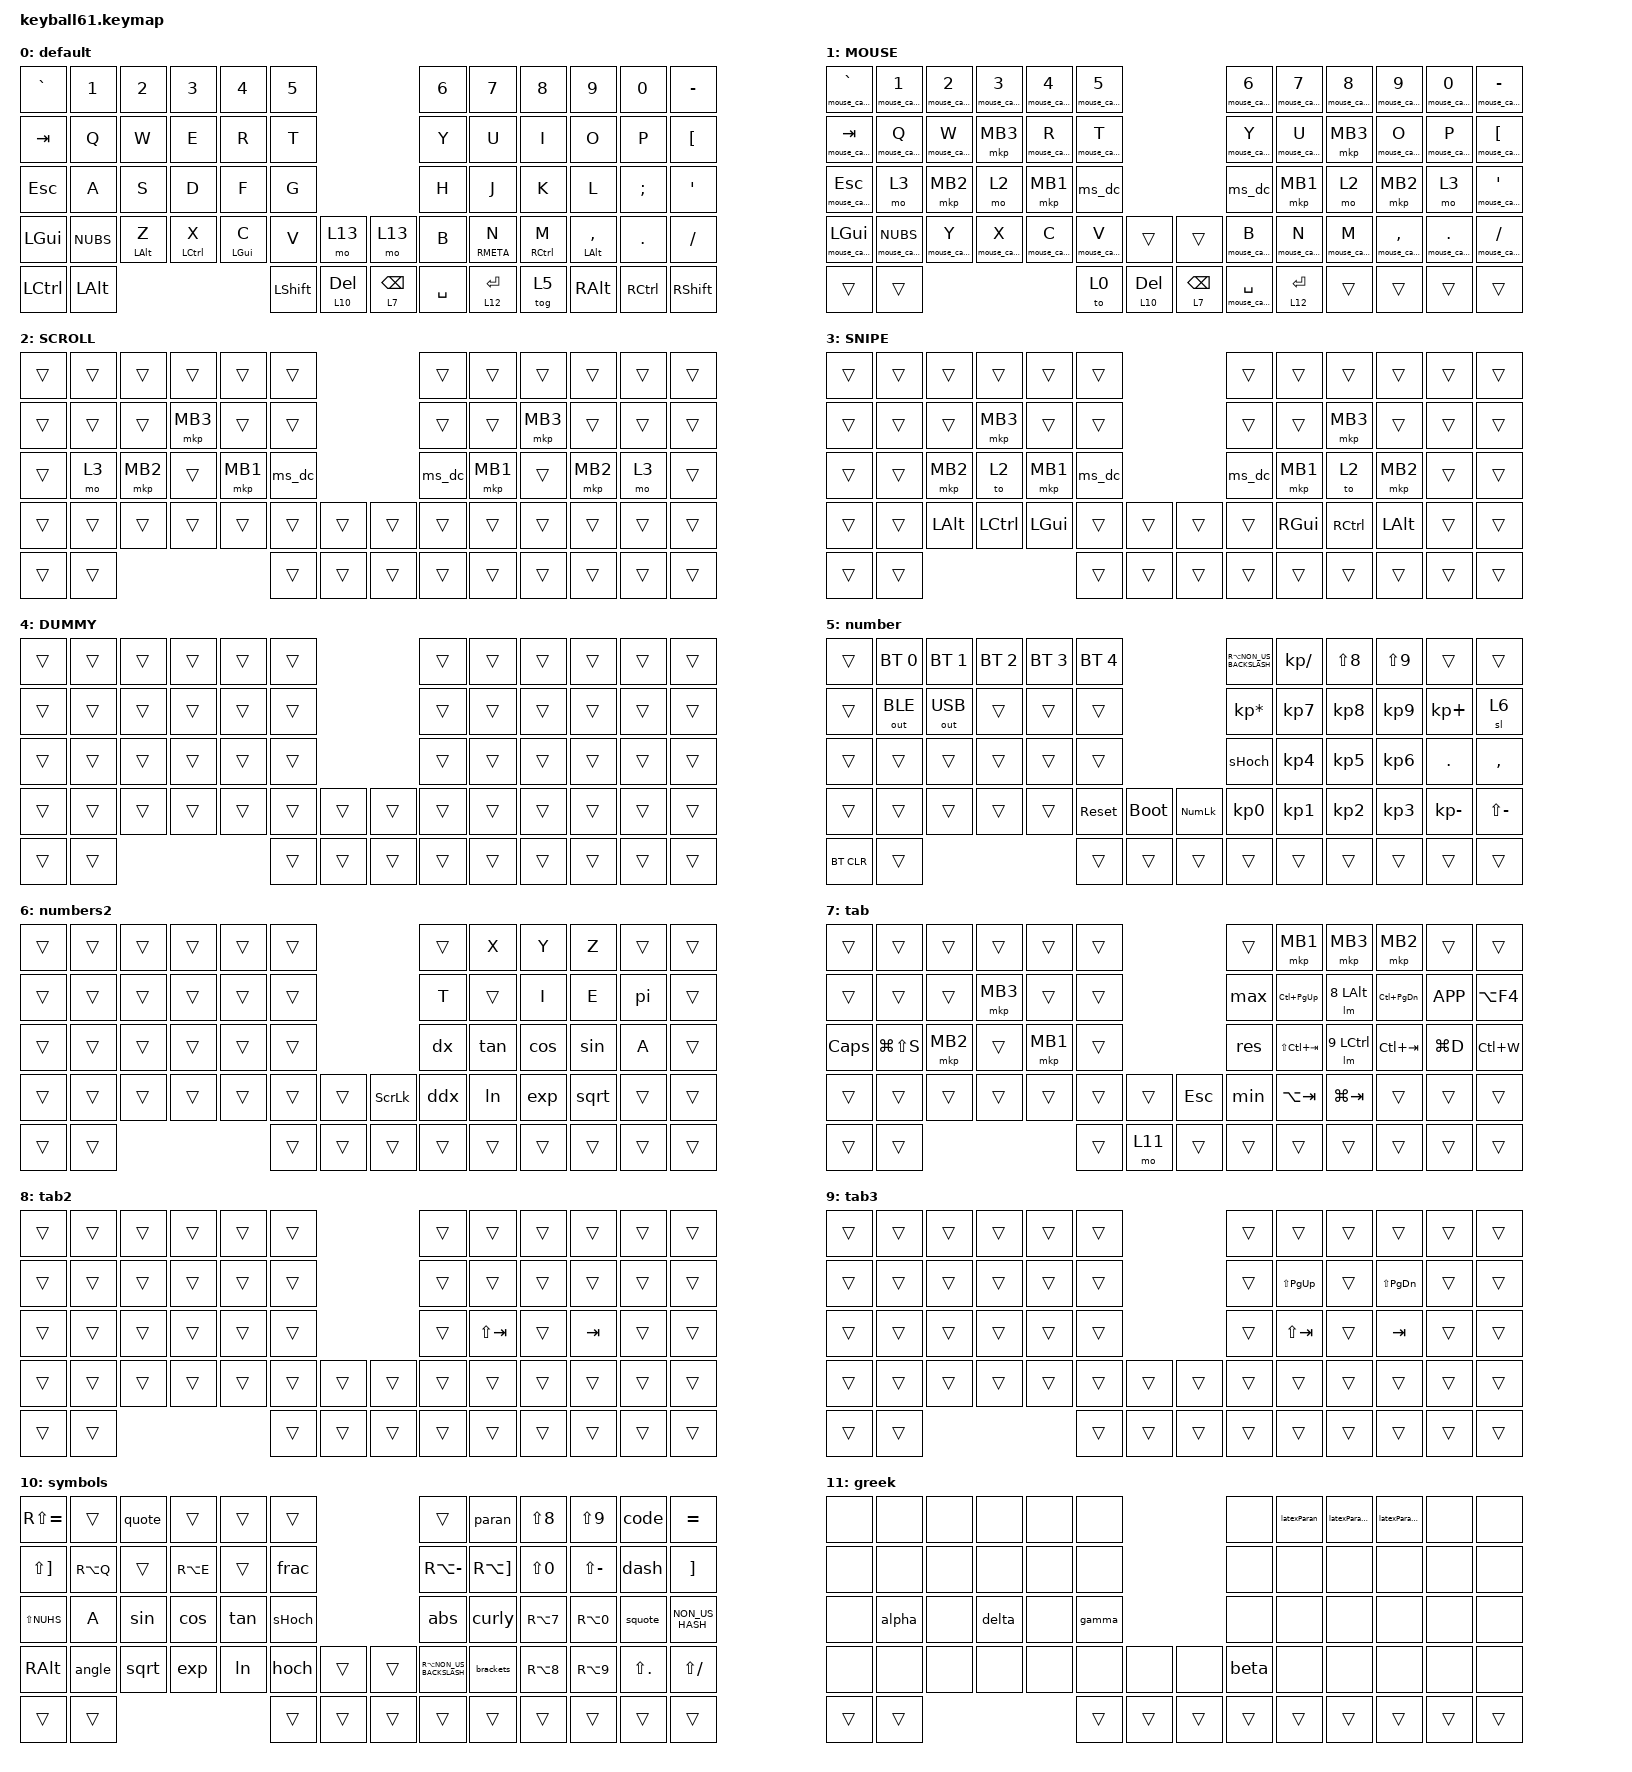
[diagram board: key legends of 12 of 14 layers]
#define DEFAULT 0
#define SYM     1
#define FUN     2
#define MOUSE   3
#define SCROLL  4
#define SNIPE   5

#include <behaviors/mouse_keys.dtsi>
#include <dt-bindings/zmk/mouse.h>
#include <behaviors.dtsi>
#include <dt-bindings/zmk/bt.h>
#include <dt-bindings/zmk/keys.h>
#include <dt-bindings/zmk/outputs.h>
#include <dt-bindings/zmk/pointing.h>

&lt {
    tapping-term-ms = <240>;
    flavor = "balanced";
    quick-tap-ms = <150>;
};

&mt {
    tapping-term-ms = <200>;
    flavor = "tap-preferred";
    quick-tap-ms = <150>;
};

/ {
    macros {
        lm: lm {
            compatible = "zmk,behavior-macro-two-param";
            #binding-cells = <2>;
            bindings =
                <&macro_param_1to1>,
                <&macro_press>,
                <&mo MACRO_PLACEHOLDER &macro_param_2to1>,
                <&macro_press>,
                <&kp MACRO_PLACEHOLDER>,
                <&macro_pause_for_release>,
                <&macro_param_2to1>,
                <&macro_release>,
                <&kp MACRO_PLACEHOLDER &macro_param_1to1>,
                <&macro_release>,
                <&mo MACRO_PLACEHOLDER>;

            label = "LM";
        };

        curly: curly {
            compatible = "zmk,behavior-macro";
            #binding-cells = <0>;
            bindings = <&kp RA(N7) &kp RA(N0) &kp LEFT>;
            label = "CURLY";
        };

        paran: paran {
            compatible = "zmk,behavior-macro";
            #binding-cells = <0>;
            bindings = <&kp LS(N8) &kp LS(N9) &kp LEFT>;
            label = "PARAN";
        };

        angle: angle {
            compatible = "zmk,behavior-macro";
            #binding-cells = <0>;
            bindings = <&kp NON_US_BACKSLASH &kp LS(NON_US_BACKSLASH) &kp LEFT>;
            label = "angle";
        };

        brackets: brackets {
            compatible = "zmk,behavior-macro";
            #binding-cells = <0>;
            bindings = <&kp RA(N8) &kp RA(N9) &kp LEFT>;
            label = "BRACKETS";
        };

        abs: abs {
            compatible = "zmk,behavior-macro";
            #binding-cells = <0>;
            bindings = <&kp RA(NON_US_BACKSLASH) &kp RA(NON_US_BACKSLASH) &kp LEFT>;
            label = "ABS";
        };

        code: code {
            compatible = "zmk,behavior-macro";
            #binding-cells = <0>;
            bindings = <&kp LS(EQUAL) &kp LS(EQUAL) &kp LS(EQUAL) &kp SPACE &kp ENTER>;
            label = "CODE";
        };

        quote: quote {
            compatible = "zmk,behavior-macro";
            #binding-cells = <0>;
            bindings = <&kp LS(N2) &kp LS(N2) &kp LEFT>;
            label = "QUOTE";
        };

        squote: squote {
            compatible = "zmk,behavior-macro";
            #binding-cells = <0>;
            bindings = <&kp LS(NON_US_HASH) &kp LS(NON_US_HASH) &kp LEFT>;
            label = "SQUOTE";
        };

        max: max {
            compatible = "zmk,behavior-macro";
            #binding-cells = <0>;
            bindings = <&kp LA(SPACE) &kp X>;
            label = "MAX";
        };

        min: min {
            compatible = "zmk,behavior-macro";
            #binding-cells = <0>;
            bindings = <&kp LA(SPACE) &kp N>;
            label = "MIN";
        };

        res: res {
            compatible = "zmk,behavior-macro";
            #binding-cells = <0>;
            bindings = <&kp LA(SPACE) &kp R>;
            label = "RES";
        };

        sin: sin {
            compatible = "zmk,behavior-macro";
            #binding-cells = <0>;
            bindings = <&kp S &kp I &kp N &kp LS(N8) &kp LS(N9) &kp LEFT>;
            label = "SIN";
        };

        cos: cos {
            compatible = "zmk,behavior-macro";
            #binding-cells = <0>;
            bindings = <&kp C &kp O &kp S &kp LS(N8) &kp LS(N9) &kp LEFT>;
            label = "COS";
        };

        tan: tan {
            compatible = "zmk,behavior-macro";
            #binding-cells = <0>;
            bindings = <&kp T &kp A &kp N &kp LS(N8) &kp LS(N9) &kp LEFT>;
            label = "TAN";
        };

        sqrt: sqrt {
            compatible = "zmk,behavior-macro";
            #binding-cells = <0>;
            bindings = <&kp S &kp Q &kp R &kp T &kp LS(N8) &kp LS(N9) &kp LEFT>;
            label = "SQRT";
        };

        hoch: hoch {
            compatible = "zmk,behavior-macro";
            #binding-cells = <0>;
            bindings = <&kp GRAVE &kp LS(N8) &kp LS(N9) &kp LEFT>;
            label = "HOCH";
        };

        exp: exp {
            compatible = "zmk,behavior-macro";
            #binding-cells = <0>;
            bindings = <&kp E &kp X &kp P &kp LS(N8) &kp LS(N9) &kp LEFT>;
            label = "EXP";
        };

        ln: ln {
            compatible = "zmk,behavior-macro";
            #binding-cells = <0>;
            bindings = <&kp L &kp N &kp LS(N8) &kp LS(N9) &kp LEFT>;
            label = "LN";
        };

        latexParanOpen: latexParanOpen {
            compatible = "zmk,behavior-macro";
            #binding-cells = <0>;
            bindings = <&kp RA(MINUS) &kp L &kp E &kp F &kp T &kp LS(N8)>;
            label = "LATEXPARAN";
        };

        latexParanClose: latexParanClose {
            compatible = "zmk,behavior-macro";
            #binding-cells = <0>;
            bindings = <&kp RA(MINUS) &kp R &kp I &kp G &kp H &kp T &kp LS(N9)>;
            label = "LATEXPARANCLOSE";
        };

        latexParan: latexParan {
            compatible = "zmk,behavior-macro";
            #binding-cells = <0>;
            bindings = <&kp RA(MINUS) &kp L &kp E &kp F &kp T &kp LS(N8) &kp RA(MINUS) &kp R &kp I &kp G &kp H &kp T &kp LS(N9) &kp LEFT_ARROW &kp LEFT_ARROW &kp LEFT_ARROW &kp LEFT_ARROW &kp LEFT &kp LEFT_ARROW &kp LEFT_ARROW>;
            label = "LATEXPARAN";
        };

        alpha: alpha {
            compatible = "zmk,behavior-macro";
            #binding-cells = <0>;
            bindings = <&kp RA(MINUS) &kp A &kp L &kp P &kp H &kp A>;
            label = "ALPHA";
        };

        beta: beta {
            compatible = "zmk,behavior-macro";
            #binding-cells = <0>;
            bindings = <&kp RA(MINUS) &kp B &kp E &kp T &kp A>;
            label = "BETA";
        };

        gamma: gamma {
            compatible = "zmk,behavior-macro";
            #binding-cells = <0>;
            bindings = <&kp RA(MINUS) &kp G &kp A &kp M &kp M &kp A>;
            label = "GAMMA";
        };

        delta: delta {
            compatible = "zmk,behavior-macro";
            #binding-cells = <0>;
            bindings = <&kp RA(MINUS) &kp D &kp E &kp L &kp T &kp A>;
            label = "DELTA";
        };

        sHoch: sHoch {
            compatible = "zmk,behavior-macro";
            #binding-cells = <0>;
            bindings = <&kp GRAVE &kp SPACE>;
            label = "SHOCH";
        };

        frac: frac {
            compatible = "zmk,behavior-macro";
            #binding-cells = <0>;
            bindings = <&kp RA(MINUS) &kp F &kp R &kp A &kp C &kp RA(N7) &kp RA(N0) &kp RA(N7) &kp RA(N0) &kp LEFT &kp LEFT_ARROW &kp LEFT_ARROW>;
            label = "FRAC";
        };

        pi: pi {
            compatible = "zmk,behavior-macro";
            #binding-cells = <0>;
            bindings = <&kp P &kp I>;
            label = "PI";
        };

        dx: dx {
            compatible = "zmk,behavior-macro";
            #binding-cells = <0>;
            bindings = <&kp D &kp X>;
            label = "DX";
        };

        ddx: ddx {
            compatible = "zmk,behavior-macro";
            #binding-cells = <0>;
            bindings = <&kp D &kp LS(N7) &kp D &kp X>;
            label = "DDX";
        };

        ms_dc: doubleClick {
            compatible = "zmk,behavior-macro";
            #binding-cells = <0>;
            bindings = <&mkp MB1 &mkp MB1>;
            label = "DOUBLECLICK";
        };

        mouse_cancel: mouse_cancel {
            compatible = "zmk,behavior-macro-one-param";
            #binding-cells = <1>;
            bindings = <&macro_param_1to1 &kp MACRO_PLACEHOLDER &to 0>;
            label = "MOUSE_CANCEL";
        };

        mouse_cancel_mkp: mouse_cancel_mkp {
            compatible = "zmk,behavior-macro-one-param";
            #binding-cells = <1>;
            bindings = <&macro_param_1to1 &mkp MACRO_PLACEHOLDER &to 0>;
            label = "MOUSE_CANCEL_MKP";
        };

        dash: dash {
            compatible = "zmk,behavior-macro";
            #binding-cells = <0>;
            bindings = <&kp FSLH &kp FSLH &kp FSLH>;
            label = "DASH";
        };

        mouse_cancel_hrm_l: mouse_cancel_hrm_l {
            compatible = "zmk,behavior-macro";
            #binding-cells = <0>;
            bindings = <&HRM_R RCTRL X &to 0>;
            label = "MOUSE_CANCEL_HRM_L";
        };
    };

    behaviors {
        MoTapHp: MoTapHp {
            compatible = "zmk,behavior-hold-tap";
            label = "MOTAPHP";
            bindings = <&mo>, <&kp>;

            #binding-cells = <2>;
            tapping-term-ms = <280>;
            quick-tap-ms = <175>;
            flavor = "hold-preferred";
            hold-trigger-key-positions = <20 32 18 30 44 19 31 33 34 7 9 8 21 23 35 54 24 15 26 45 43 28 22 46>;
        };

        HRM_L: HRM_L {
            compatible = "zmk,behavior-hold-tap";
            label = "HRM_L";
            bindings = <&kp>, <&kp>;

            #binding-cells = <2>;
            tapping-term-ms = <280>;
            quick-tap-ms = <175>;
            require-prior-idle-ms = <150>;
            flavor = "balanced";
            hold-trigger-key-positions = <56 55 53 0 1 2 3 4 5 12 13 14 15 16 17 24 25 26 27 28 29 36 37 38 39 40 41 42 52 54>;
            hold-trigger-on-release;
        };

        HRM_R: HRM_R {
            compatible = "zmk,behavior-hold-tap";
            label = "HRM_R";
            bindings = <&kp>, <&kp>;

            #binding-cells = <2>;
            tapping-term-ms = <280>;
            quick-tap-ms = <175>;
            require-prior-idle-ms = <150>;
            flavor = "balanced";
            hold-trigger-key-positions = <56 55 53 6 7 8 9 10 11 18 19 20 21 22 23 30 31 32 33 34 35 43 44 45 46 47 48 49 52 54 12>;
            hold-trigger-on-release;
        };

        MoTap: MoTap {
            compatible = "zmk,behavior-hold-tap";
            label = "MOTAP";
            bindings = <&mo>, <&kp>;

            #binding-cells = <2>;
            tapping-term-ms = <280>;
            quick-tap-ms = <175>;
            flavor = "balanced";
        };

        nav_word: nav_word {
            compatible = "zmk,behavior-auto-layer";
            #binding-cells = <1>;
            continue-list = <LEFT DOWN UP RIGHT PG_DN PG_UP HOME END TAB>;
            ignore-modifiers;
        };

        navWord: navWord {
            compatible = "zmk,behavior-hold-tap";
            label = "NAVWORD";
            bindings = <&nav_word>, <&kp>;

            #binding-cells = <2>;
            tapping-term-ms = <280>;
            quick-tap-ms = <175>;
            require-prior-idle-ms = <150>;
            flavor = "balanced";
        };

        ms_word: ms_word {
            compatible = "zmk,behavior-auto-layer";
            #binding-cells = <1>;
            continue-list = <LEFT DOWN UP RIGHT PG_DN PG_UP HOME END TAB>;
            ignore-modifiers;
        };

        msWord: msWord {
            compatible = "zmk,behavior-hold-tap";
            label = "MSWORD";
            bindings = <&ms_word>, <&kp>;

            #binding-cells = <2>;
            tapping-term-ms = <280>;
            quick-tap-ms = <175>;
            require-prior-idle-ms = <150>;
            flavor = "balanced";
        };

        mouse_click_ht: mouse_click_ht {
            compatible = "zmk,behavior-hold-tap";
            label = "MOUSE_CLICK_HT";
            bindings = <&mkp>, <&mouse_cancel_mkp>;

            #binding-cells = <2>;
            tapping-term-ms = <280>;
        };

        mouse_layer_ht: mouse_layer_ht {
            compatible = "zmk,behavior-hold-tap";
            label = "MOUSE_LAYER_HT";
            bindings = <&mo>, <&mouse_cancel>;

            #binding-cells = <2>;
            tapping-term-ms = <280>;
            quick-tap-ms = <175>;
            require-prior-idle-ms = <150>;
            flavor = "balanced";
        };

        mouse_MoTapHp: mouse_MoTapHp {
            compatible = "zmk,behavior-hold-tap";
            label = "MOUSE_MOTAPHP";
            bindings = <&mo>, <&mouse_cancel>;

            #binding-cells = <2>;
            tapping-term-ms = <280>;
            quick-tap-ms = <175>;
            flavor = "hold-preferred";
            hold-trigger-key-positions = <20 32 18 30 44 19 31 33 34 7 9 8 21 23 35 54 24 15 26 45 25 28>;
        };

        mouse_MoTap: mouse_MoTap {
            compatible = "zmk,behavior-hold-tap";
            label = "MOUSE_MOTAP";
            bindings = <&mo>, <&mouse_cancel>;

            #binding-cells = <2>;
            tapping-term-ms = <280>;
            quick-tap-ms = <175>;
            require-prior-idle-ms = <150>;
            flavor = "balanced";
        };

        hrm_r_mouse_cancel: hrm_r_mouse_cancel {
            compatible = "zmk,behavior-hold-tap";
            label = "HRM_R_MOUSE_CANCEL";
            bindings = <&mouse_cancel>, <&mouse_cancel>;

            #binding-cells = <2>;
            tapping-term-ms = <280>;
            quick-tap-ms = <175>;
            require-prior-idle-ms = <0>;
            flavor = "balanced";
            hold-trigger-key-positions = <56 55 53 6 7 8 9 10 11 18 19 20 21 22 23 30 31 32 33 34 35 43 44 45 46 47 48 49 52 54 12>;
            hold-trigger-on-release;
        };

        hrm_l_mouse_cancel: hrm_l_mouse_cancel {
            compatible = "zmk,behavior-hold-tap";
            label = "HRM_L_MOUSE_CANCEL";
            bindings = <&mouse_cancel>, <&mouse_cancel>;

            #binding-cells = <2>;
            tapping-term-ms = <280>;
            quick-tap-ms = <175>;
            require-prior-idle-ms = <150>;
            flavor = "balanced";
            hold-trigger-key-positions = <56 55 53 0 1 2 3 4 5 12 13 14 15 16 17 24 25 26 27 28 29 36 37 38 39 40 41 42 52 54>;
            hold-trigger-on-release;
        };
    };

    combos {
        compatible = "zmk,combos";

        rgui_tap {
            bindings = <&kp RMETA>;
            key-positions = <54 45>;
            require-prior-idle-ms = <150>;
        };

        rctrl_tap {
            bindings = <&kp RCTRL>;
            key-positions = <54 46>;
            require-prior-idle-ms = <150>;
        };

        ralt_tap {
            bindings = <&kp RIGHT_ALT>;
            key-positions = <54 47>;
            require-prior-idle-ms = <150>;
        };

        lgui_tap {
            bindings = <&kp LMETA>;
            key-positions = <53 40>;
            require-prior-idle-ms = <150>;
        };

        lctrl_tap {
            bindings = <&kp LCTRL>;
            key-positions = <53 39>;
            require-prior-idle-ms = <150>;
        };

        lalt_tap {
            bindings = <&kp LALT>;
            key-positions = <53 38>;
            require-prior-idle-ms = <150>;
        };

        number_layer {
            bindings = <&mo 5>;
            key-positions = <26 27>;
        };
    };

    keymap {
        compatible = "zmk,keymap";

        default_layer {
            label = "default";
            bindings = <
&kp GRAVE     &kp N1        &kp N2             &kp N3          &kp N4         &kp N5                                             &kp N6     &kp N7           &kp N8          &kp N9             &kp N0         &kp MINUS
&kp TAB       &kp Q         &kp W              &kp E           &kp R          &kp T                                              &kp Y      &kp U            &kp I           &kp O              &kp P          &kp LBKT
&kp ESC       &kp A         &kp S              &kp D           &kp F          &kp G                                              &kp H      &kp J            &kp K           &kp L              &kp SEMICOLON  &kp SQT
&kp LEFT_GUI  &kp NUBS      &HRM_R LEFT_ALT Z  &HRM_R LCTRL X  &HRM_R LGUI C  &kp V      &mo 13            &mo 13                &kp B      &HRM_L RMETA N   &HRM_L RCTRL M  &HRM_L LALT COMMA  &kp DOT        &kp FSLH
&kp LCTRL     &kp LEFT_ALT                                                    &kp LSHFT  &MoTap 10 DELETE  &MoTapHp 7 BACKSPACE  &kp SPACE  &MoTap 12 ENTER  &tog 5          &kp RIGHT_ALT      &kp RCTRL      &kp RSHFT
            >;
        };

        mouse_layer {
            label = "MOUSE";
            bindings = <
&mouse_cancel GRAVE     &mouse_cancel N1    &mouse_cancel N2  &mouse_cancel N3  &mouse_cancel N4  &mouse_cancel N5                                                      &mouse_cancel N6     &mouse_cancel N7       &mouse_cancel N8  &mouse_cancel N9     &mouse_cancel N0   &mouse_cancel MINUS
&mouse_cancel TAB       &mouse_cancel Q     &mouse_cancel W   &mkp MB3          &mouse_cancel R   &mouse_cancel T                                                       &mouse_cancel Y      &mouse_cancel U        &mkp MB3          &mouse_cancel O      &mouse_cancel P    &mouse_cancel LBKT
&mouse_cancel ESC       &mo 3               &mkp MB2          &mo 2             &mkp MB1          &ms_dc                                                                &ms_dc               &mkp MB1               &mo 2             &mkp MB2             &mo 3              &mouse_cancel SQT
&mouse_cancel LEFT_GUI  &mouse_cancel NUBS  &mouse_cancel Y   &mouse_cancel X   &mouse_cancel C   &mouse_cancel V   &trans                  &trans                      &mouse_cancel B      &mouse_cancel N        &mouse_cancel M   &mouse_cancel COMMA  &mouse_cancel DOT  &mouse_cancel FSLH
&trans                  &trans                                                                    &to 0             &mouse_MoTap 10 DELETE  &mouse_MoTapHp 7 BACKSPACE  &mouse_cancel SPACE  &mouse_MoTap 12 ENTER  &trans            &trans               &trans             &trans
            >;
        };

        scroll_layer {
            label = "SCROLL";
            bindings = <
&trans  &trans  &trans    &trans    &trans    &trans                  &trans  &trans    &trans    &trans    &trans  &trans
&trans  &trans  &trans    &mkp MB3  &trans    &trans                  &trans  &trans    &mkp MB3  &trans    &trans  &trans
&trans  &mo 3   &mkp MB2  &trans    &mkp MB1  &ms_dc                  &ms_dc  &mkp MB1  &trans    &mkp MB2  &mo 3   &trans
&trans  &trans  &trans    &trans    &trans    &trans  &trans  &trans  &trans  &trans    &trans    &trans    &trans  &trans
&trans  &trans                                &trans  &trans  &trans  &trans  &trans    &trans    &trans    &trans  &trans
            >;
        };

        snipe_layer {
            label = "SNIPE";
            bindings = <
&trans  &trans  &trans        &trans     &trans    &trans                  &trans  &trans    &trans     &trans    &trans  &trans
&trans  &trans  &trans        &mkp MB3   &trans    &trans                  &trans  &trans    &mkp MB3   &trans    &trans  &trans
&trans  &trans  &mkp MB2      &to 2      &mkp MB1  &ms_dc                  &ms_dc  &mkp MB1  &to 2      &mkp MB2  &trans  &trans
&trans  &trans  &kp LEFT_ALT  &kp LCTRL  &kp LGUI  &trans  &trans  &trans  &trans  &kp RGUI  &kp RCTRL  &kp LALT  &trans  &trans
&trans  &trans                                     &trans  &trans  &trans  &trans  &trans    &trans     &trans    &trans  &trans
            >;
        };

        dummy_layer {
            label = "DUMMY";
            bindings = <
&trans  &trans  &trans  &trans  &trans  &trans                  &trans  &trans  &trans  &trans  &trans  &trans
&trans  &trans  &trans  &trans  &trans  &trans                  &trans  &trans  &trans  &trans  &trans  &trans
&trans  &trans  &trans  &trans  &trans  &trans                  &trans  &trans  &trans  &trans  &trans  &trans
&trans  &trans  &trans  &trans  &trans  &trans  &trans  &trans  &trans  &trans  &trans  &trans  &trans  &trans
&trans  &trans                          &trans  &trans  &trans  &trans  &trans  &trans  &trans  &trans  &trans
            >;
        };

        number {
            bindings = <
&trans      &bt BT_SEL 0  &bt BT_SEL 1  &bt BT_SEL 2  &bt BT_SEL 3  &bt BT_SEL 4                               &kp RA(NON_US_BACKSLASH)  &kp KP_DIVIDE    &kp LS(N8)       &kp LS(N9)       &trans        &trans
&trans      &out OUT_BLE  &out OUT_USB  &trans        &trans        &trans                                     &kp KP_MULTIPLY           &kp KP_NUMBER_7  &kp KP_NUMBER_8  &kp KP_NUMBER_9  &kp KP_PLUS   &sl 6
&trans      &trans        &trans        &trans        &trans        &trans                                     &sHoch                    &kp KP_NUMBER_4  &kp KP_NUMBER_5  &kp KP_NUMBER_6  &kp PERIOD    &kp COMMA
&trans      &trans        &trans        &trans        &trans        &sys_reset    &bootloader  &kp KP_NUMLOCK  &kp KP_NUMBER_0           &kp KP_NUMBER_1  &kp KP_NUMBER_2  &kp KP_NUMBER_3  &kp KP_MINUS  &kp LS(MINUS)
&bt BT_CLR  &trans                                                  &trans        &trans       &trans          &trans                    &trans           &trans           &trans           &trans        &trans
            >;

            label = "number";
        };

        numbers2 {
            bindings = <
&trans  &trans  &trans  &trans  &trans  &trans                          &trans  &kp X   &kp Y   &kp Z   &trans  &trans
&trans  &trans  &trans  &trans  &trans  &trans                          &kp T   &trans  &kp I   &kp E   &pi     &trans
&trans  &trans  &trans  &trans  &trans  &trans                          &dx     &tan    &cos    &sin    &kp A   &trans
&trans  &trans  &trans  &trans  &trans  &trans  &trans  &kp SCROLLLOCK  &ddx    &ln     &exp    &sqrt   &trans  &trans
&trans  &trans                          &trans  &trans  &trans          &trans  &trans  &trans  &trans  &trans  &trans
            >;

            label = "numbers2";
        };

        tab {
            bindings = <
&trans    &trans         &trans    &trans    &trans    &trans                   &trans  &mkp MB1         &mkp MB3     &mkp MB2           &trans     &trans
&trans    &trans         &trans    &mkp MB3  &trans    &trans                   &max    &kp LC(PG_UP)    &lm 8 LALT   &kp LC(PAGE_DOWN)  &kp K_APP  &kp LA(F4)
&kp CAPS  &kp LG(LS(S))  &mkp MB2  &trans    &mkp MB1  &trans                   &res    &kp LS(LC(TAB))  &lm 9 LCTRL  &kp LC(TAB)        &kp LG(D)  &kp LC(W)
&trans    &trans         &trans    &trans    &trans    &trans  &trans  &kp ESC  &min    &kp LA(TAB)      &kp LG(TAB)  &trans             &trans     &trans
&trans    &trans                                       &trans  &mo 11  &trans   &trans  &trans           &trans       &trans             &trans     &trans
            >;

            label = "tab";
        };

        tab2 {
            bindings = <
&trans  &trans  &trans  &trans  &trans  &trans                  &trans  &trans       &trans  &trans   &trans  &trans
&trans  &trans  &trans  &trans  &trans  &trans                  &trans  &trans       &trans  &trans   &trans  &trans
&trans  &trans  &trans  &trans  &trans  &trans                  &trans  &kp LS(TAB)  &trans  &kp TAB  &trans  &trans
&trans  &trans  &trans  &trans  &trans  &trans  &trans  &trans  &trans  &trans       &trans  &trans   &trans  &trans
&trans  &trans                          &trans  &trans  &trans  &trans  &trans       &trans  &trans   &trans  &trans
            >;

            label = "tab2";
        };

        tab3 {
            bindings = <
&trans  &trans  &trans  &trans  &trans  &trans                  &trans  &trans         &trans  &trans         &trans  &trans
&trans  &trans  &trans  &trans  &trans  &trans                  &trans  &kp LS(PG_UP)  &trans  &kp LS(PG_DN)  &trans  &trans
&trans  &trans  &trans  &trans  &trans  &trans                  &trans  &kp LS(TAB)    &trans  &kp TAB        &trans  &trans
&trans  &trans  &trans  &trans  &trans  &trans  &trans  &trans  &trans  &trans         &trans  &trans         &trans  &trans
&trans  &trans                          &trans  &trans  &trans  &trans  &trans         &trans  &trans         &trans  &trans
            >;

            label = "tab3";
        };

        symbols {
            bindings = <
&kp RS(EQUAL)          &trans     &quote  &trans     &trans  &trans                  &trans                    &paran                 &kp LS(N8)  &kp LS(N9)     &code           &kp EQUAL
&kp LS(RIGHT_BRACKET)  &kp RA(Q)  &trans  &kp RA(E)  &trans  &frac                   &kp RA(MINUS)             &kp RA(RIGHT_BRACKET)  &kp LS(N0)  &kp LS(MINUS)  &dash           &kp RIGHT_BRACKET
&kp LS(NUHS)           &kp A      &sin    &cos       &tan    &sHoch                  &abs                      &curly                 &kp RA(N7)  &kp RA(N0)     &squote         &kp NON_US_HASH
&kp RALT               &angle     &sqrt   &exp       &ln     &hoch   &trans  &trans  &kp RA(NON_US_BACKSLASH)  &brackets              &kp RA(N8)  &kp RA(N9)     &kp LS(PERIOD)  &kp LS(SLASH)
&trans                 &trans                                &trans  &trans  &trans  &trans                    &trans                 &trans      &trans         &trans          &trans
            >;

            label = "symbols";
        };

        greek {
            bindings = <
&none   &none   &none  &none   &none  &none                   &none   &latexParan  &latexParanOpen  &latexParanClose  &none   &none
&none   &none   &none  &none   &none  &none                   &none   &none        &none            &none             &none   &none
&none   &alpha  &none  &delta  &none  &gamma                  &none   &none        &none            &none             &none   &none
&none   &none   &none  &none   &none  &none   &none   &none   &beta   &none        &none            &none             &none   &none
&trans  &trans                        &trans  &trans  &trans  &trans  &trans       &trans           &trans            &trans  &trans
            >;

            label = "greek";
        };

        nav {
            bindings = <
&trans  &trans  &trans  &trans  &trans  &trans                  &trans     &kp LC(HOME)   &kp K_APPLICATION  &kp LC(END)    &trans     &kp INS
&trans  &trans  &trans  &trans  &trans  &trans                  &kp HOME   &kp LC(LEFT)   &kp LS(TAB)        &kp LC(RIGHT)  &kp END    &kp LC(V)
&trans  &trans  &trans  &trans  &trans  &trans                  &kp PG_UP  &kp LEFT       &kp UP_ARROW       &kp RIGHT      &kp DOWN   &kp TAB
&trans  &trans  &trans  &trans  &trans  &trans  &trans  &trans  &kp PG_DN  &kp BACKSPACE  &kp DEL            &kp LC(A)      &kp LC(X)  &kp LC(C)
&trans  &trans                          &trans  &trans  &trans  &trans     &trans         &trans             &trans         &trans     &trans
            >;

            label = "nav";
        };

        media {
            bindings = <
&trans      &bt BT_SEL 0  &bt BT_SEL 1  &bt BT_SEL 2      &bt BT_SEL 3  &bt BT_SEL 4                       &trans                &kp F10  &kp F11  &kp F12  &trans  &trans
&trans      &out OUT_BLE  &out OUT_USB  &trans            &trans        &kp C_VOL_UP                       &kp C_BRIGHTNESS_INC  &kp F7   &kp F8   &kp F9   &trans  &trans
&trans      &kp C_STOP    &kp C_PREV    &kp C_PLAY_PAUSE  &kp C_NEXT    &kp C_VOLUME_DOWN                  &kp C_BRIGHTNESS_DEC  &kp F4   &kp F5   &kp F6   &trans  &trans
&trans      &trans        &trans        &trans            &trans        &kp C_MUTE         &trans  &trans  &kp C_SLEEP_MODE      &kp F1   &kp F2   &kp F3   &trans  &trans
&bt BT_CLR  &bootloader                                                 &trans             &trans  &trans  &trans                &trans   &trans   &trans   &trans  &trans
            >;

            label = "media";
        };
    };
};
